VERSION ""

NS_ :

BS_ :

BU_ : mobileye vdcl_pc

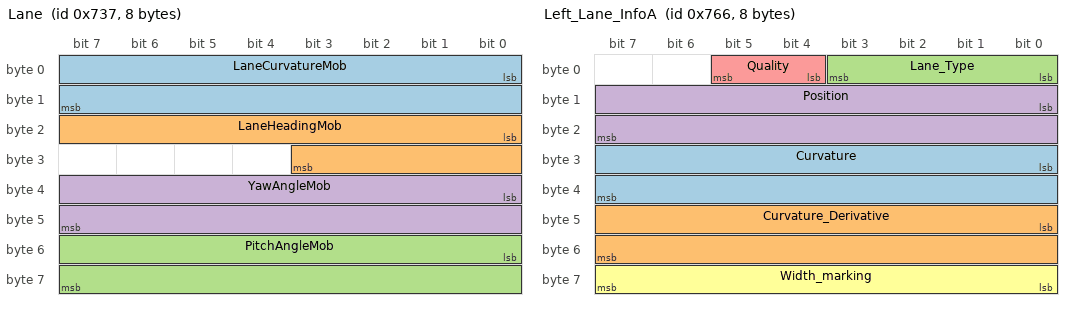
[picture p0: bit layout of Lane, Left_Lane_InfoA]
BO_ 1847 Lane: 8 mobileye
  SG_ LaneCurvatureMob : 0|16@1- (3.8099999999999991e-006,0) [-0.12|0.12] "1/m" vdcl_pc
  SG_ LaneHeadingMob : 16|12@1- (0.00050000000000000001,0) [-1|1] "rad" vdcl_pc
  SG_ PitchAngleMob : 48|16@1+ (1.9073486328125e-006,-0.062498092651367201) [-0.050000000000000003|0.050000000000000003] "rad" vdcl_pc
  SG_ YawAngleMob : 32|16@1+ (0.0009765625,-31.9990234375) [0|1000] "rad" vdcl_pc

BO_ 1894 Left_Lane_InfoA: 8 mobileye
  SG_ Curvature : 24|16@1+ (9.7655999999999963e-007,-0.03199894151999999) [-0.02|0.02] "" vdcl_pc
  SG_ Curvature_Derivative : 40|16@1+ (3.7252902984619149e-009,-0.0001220665899999999) [-0.00012|0.00012] "" vdcl_pc
  SG_ Lane_Type : 0|4@1+ (1,0) [0|1000] "" vdcl_pc
  SG_ Position : 8|16@1- (0.00390625,0) [-127|128] "m" vdcl_pc
  SG_ Quality : 4|2@1+ (1,0) [0|1000] "" vdcl_pc
  SG_ Width_marking : 56|8@1+ (0.01,0) [0|2.5] "" vdcl_pc

BO_ 1895 Left_Lane_InfoB: 8 mobileye
  SG_ Heading_Angle : 0|16@1+ (0.00097656000000000001,-31.9990234375) [-0.35699999999999987|0.35699999999999987] "radians" vdcl_pc
  SG_ Lane_View_Range : 16|15@1+ (0.00390625,0) [0|127.996] "meter" vdcl_pc

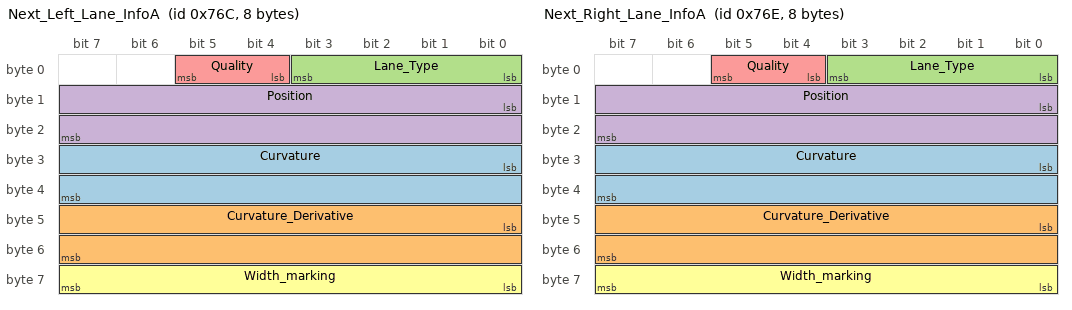
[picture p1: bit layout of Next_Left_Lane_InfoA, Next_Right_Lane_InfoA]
BO_ 1900 Next_Left_Lane_InfoA: 8 mobileye
  SG_ Curvature : 24|16@1+ (9.7655999999999963e-007,-0.031998941500000003) [-0.02|0.02] "" vdcl_pc
  SG_ Curvature_Derivative : 40|16@1+ (3.7252903000000002e-009,-0.0001220665899999999) [-0.00012|0.00012] "" vdcl_pc
  SG_ Lane_Type : 0|4@1+ (1,0) [0|1000] "" vdcl_pc
  SG_ Position : 8|16@1- (0.00390625,0) [-127|128] "" vdcl_pc
  SG_ Quality : 4|2@1+ (1,0) [0|1000] "" vdcl_pc
  SG_ Width_marking : 56|8@1+ (0.01,0) [0|2.5] "" vdcl_pc

BO_ 1901 Next_Left_Lane_InfoB: 8 mobileye
  SG_ Heading_Angle : 0|16@1+ (0.00097656000000000001,-31.999023399999999) [-0.35699999999999987|0.35699999999999987] "" vdcl_pc
  SG_ Lane_View_Range : 16|15@1+ (0.00390625,0) [0|127.996] "" vdcl_pc

BO_ 1902 Next_Right_Lane_InfoA: 8 mobileye
  SG_ Curvature : 24|16@1+ (9.7655999999999963e-007,-0.031998941500000003) [-0.02|0.02] "" vdcl_pc
  SG_ Curvature_Derivative : 40|16@1+ (3.7252903000000002e-009,-0.0001220665899999999) [-0.00012|0.00012] "" vdcl_pc
  SG_ Lane_Type : 0|4@1+ (1,0) [0|1000] "" vdcl_pc
  SG_ Position : 8|16@1- (0.00390625,0) [-127|128] "" vdcl_pc
  SG_ Quality : 4|2@1+ (1,0) [0|1000] "" vdcl_pc
  SG_ Width_marking : 56|8@1+ (0.01,0) [0|2.5] "" vdcl_pc

BO_ 1903 Next_Right_Lane_InfoB: 8 mobileye
  SG_ Heading_Angle : 0|16@1+ (0.00097656000000000001,-31.999023399999999) [-0.35699999999999987|0.35699999999999987] "" vdcl_pc
  SG_ Lane_View_Range : 16|15@1+ (0.00390625,0) [0|127.996] "" vdcl_pc

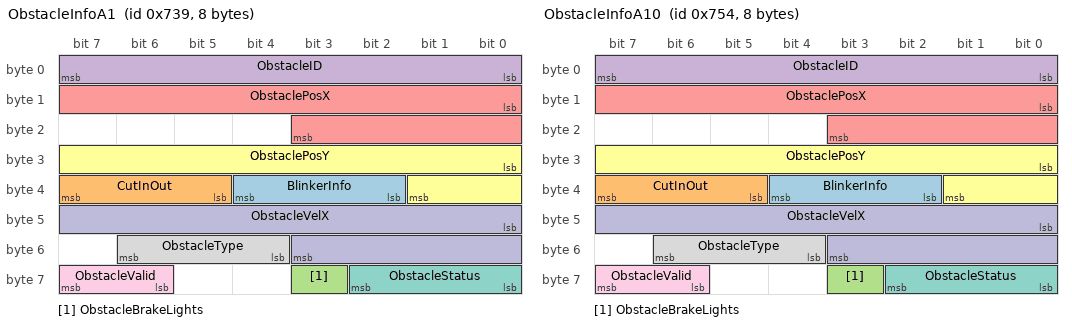
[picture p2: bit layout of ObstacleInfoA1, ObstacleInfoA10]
BO_ 1849 ObstacleInfoA1: 8 mobileye
  SG_ BlinkerInfo : 34|3@1+ (1,0) [0|1000] "" vdcl_pc
  SG_ CutInOut : 37|3@1+ (1,0) [0|1000] "" vdcl_pc
  SG_ ObstacleBrakeLights : 59|1@1+ (1,0) [0|1000] "" vdcl_pc
  SG_ ObstacleID : 0|8@1+ (1,0) [0|1000] "" vdcl_pc
  SG_ ObstaclePosX : 8|12@1+ (0.0625,0) [0|250] "m" vdcl_pc
  SG_ ObstaclePosY : 24|10@1- (0.0625,0) [-31.93|31.93] "m" vdcl_pc
  SG_ ObstacleStatus : 56|3@1+ (1,0) [0|1000] "" vdcl_pc
  SG_ ObstacleType : 52|3@1+ (1,0) [0|7] "" vdcl_pc
  SG_ ObstacleValid : 62|2@1+ (1,0) [0|1000] "" vdcl_pc
  SG_ ObstacleVelX : 40|12@1- (0.0625,0) [-127.93000000000001|127.93000000000001] "m/s" vdcl_pc

BO_ 1876 ObstacleInfoA10: 8 mobileye
  SG_ BlinkerInfo : 34|3@1+ (1,0) [0|1000] "" vdcl_pc
  SG_ CutInOut : 37|3@1+ (1,0) [0|1000] "" vdcl_pc
  SG_ ObstacleBrakeLights : 59|1@1+ (1,0) [0|1000] "" vdcl_pc
  SG_ ObstacleID : 0|8@1+ (1,0) [0|1000] "" vdcl_pc
  SG_ ObstaclePosX : 8|12@1+ (0.0625,0) [0|250] "m" vdcl_pc
  SG_ ObstaclePosY : 24|10@1- (0.0625,0) [-31.93|31.93] "m" vdcl_pc
  SG_ ObstacleStatus : 56|3@1+ (1,0) [0|1000] "" vdcl_pc
  SG_ ObstacleType : 52|3@1+ (1,0) [0|7] "" vdcl_pc
  SG_ ObstacleValid : 62|2@1+ (1,0) [0|1000] "" vdcl_pc
  SG_ ObstacleVelX : 40|12@1- (0.0625,0) [-127.93000000000001|127.93000000000001] "m/s" vdcl_pc

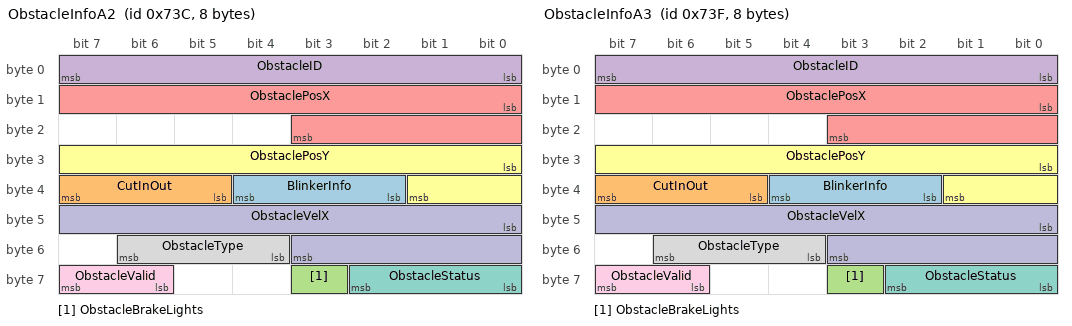
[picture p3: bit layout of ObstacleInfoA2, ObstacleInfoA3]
BO_ 1852 ObstacleInfoA2: 8 mobileye
  SG_ BlinkerInfo : 34|3@1+ (1,0) [0|1000] "" vdcl_pc
  SG_ CutInOut : 37|3@1+ (1,0) [0|1000] "" vdcl_pc
  SG_ ObstacleBrakeLights : 59|1@1+ (1,0) [0|1000] "" vdcl_pc
  SG_ ObstacleID : 0|8@1+ (1,0) [0|1000] "" vdcl_pc
  SG_ ObstaclePosX : 8|12@1+ (0.0625,0) [0|250] "m" vdcl_pc
  SG_ ObstaclePosY : 24|10@1- (0.0625,0) [-31.93|31.93] "m" vdcl_pc
  SG_ ObstacleStatus : 56|3@1+ (1,0) [0|1000] "" vdcl_pc
  SG_ ObstacleType : 52|3@1+ (1,0) [0|7] "" vdcl_pc
  SG_ ObstacleValid : 62|2@1+ (1,0) [0|1000] "" vdcl_pc
  SG_ ObstacleVelX : 40|12@1- (0.0625,0) [-127.93000000000001|127.93000000000001] "m/s" vdcl_pc

BO_ 1855 ObstacleInfoA3: 8 mobileye
  SG_ BlinkerInfo : 34|3@1+ (1,0) [0|1000] "" vdcl_pc
  SG_ CutInOut : 37|3@1+ (1,0) [0|1000] "" vdcl_pc
  SG_ ObstacleBrakeLights : 59|1@1+ (1,0) [0|1000] "" vdcl_pc
  SG_ ObstacleID : 0|8@1+ (1,0) [0|1000] "" vdcl_pc
  SG_ ObstaclePosX : 8|12@1+ (0.0625,0) [0|250] "m" vdcl_pc
  SG_ ObstaclePosY : 24|10@1- (0.0625,0) [-31.93|31.93] "m" vdcl_pc
  SG_ ObstacleStatus : 56|3@1+ (1,0) [0|1000] "" vdcl_pc
  SG_ ObstacleType : 52|3@1+ (1,0) [0|7] "" vdcl_pc
  SG_ ObstacleValid : 62|2@1+ (1,0) [0|1000] "" vdcl_pc
  SG_ ObstacleVelX : 40|12@1- (0.0625,0) [-127.93000000000001|127.93000000000001] "m/s" vdcl_pc

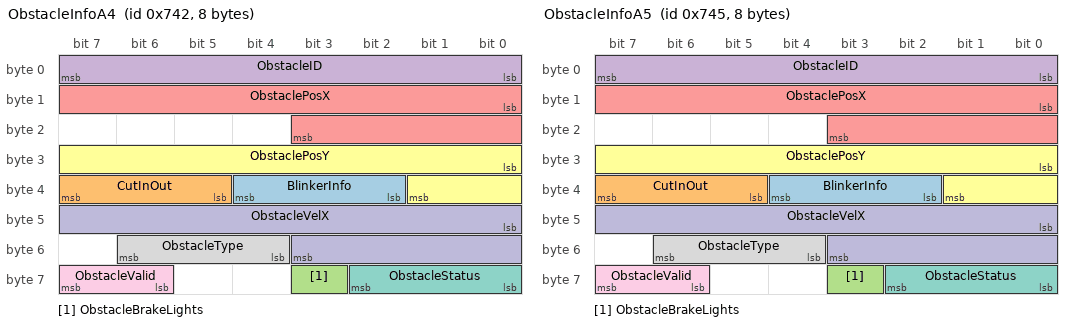
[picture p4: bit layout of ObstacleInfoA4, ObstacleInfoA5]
BO_ 1858 ObstacleInfoA4: 8 mobileye
  SG_ BlinkerInfo : 34|3@1+ (1,0) [0|1000] "" vdcl_pc
  SG_ CutInOut : 37|3@1+ (1,0) [0|1000] "" vdcl_pc
  SG_ ObstacleBrakeLights : 59|1@1+ (1,0) [0|1000] "" vdcl_pc
  SG_ ObstacleID : 0|8@1+ (1,0) [0|1000] "" vdcl_pc
  SG_ ObstaclePosX : 8|12@1+ (0.0625,0) [0|250] "m" vdcl_pc
  SG_ ObstaclePosY : 24|10@1- (0.0625,0) [-31.93|31.93] "m" vdcl_pc
  SG_ ObstacleStatus : 56|3@1+ (1,0) [0|1000] "" vdcl_pc
  SG_ ObstacleType : 52|3@1+ (1,0) [0|7] "" vdcl_pc
  SG_ ObstacleValid : 62|2@1+ (1,0) [0|1000] "" vdcl_pc
  SG_ ObstacleVelX : 40|12@1- (0.0625,0) [-127.93000000000001|127.93000000000001] "m/s" vdcl_pc

BO_ 1861 ObstacleInfoA5: 8 mobileye
  SG_ BlinkerInfo : 34|3@1+ (1,0) [0|1000] "" vdcl_pc
  SG_ CutInOut : 37|3@1+ (1,0) [0|1000] "" vdcl_pc
  SG_ ObstacleBrakeLights : 59|1@1+ (1,0) [0|1000] "" vdcl_pc
  SG_ ObstacleID : 0|8@1+ (1,0) [0|1000] "" vdcl_pc
  SG_ ObstaclePosX : 8|12@1+ (0.0625,0) [0|250] "m" vdcl_pc
  SG_ ObstaclePosY : 24|10@1- (0.0625,0) [-31.93|31.93] "m" vdcl_pc
  SG_ ObstacleStatus : 56|3@1+ (1,0) [0|1000] "" vdcl_pc
  SG_ ObstacleType : 52|3@1+ (1,0) [0|7] "" vdcl_pc
  SG_ ObstacleValid : 62|2@1+ (1,0) [0|1000] "" vdcl_pc
  SG_ ObstacleVelX : 40|12@1- (0.0625,0) [-127.93000000000001|127.93000000000001] "m/s" vdcl_pc

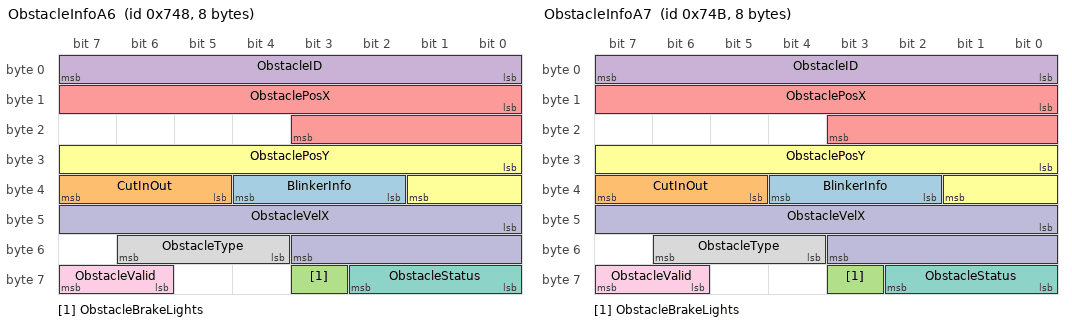
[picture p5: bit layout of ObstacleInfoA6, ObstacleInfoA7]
BO_ 1864 ObstacleInfoA6: 8 mobileye
  SG_ BlinkerInfo : 34|3@1+ (1,0) [0|1000] "" vdcl_pc
  SG_ CutInOut : 37|3@1+ (1,0) [0|1000] "" vdcl_pc
  SG_ ObstacleBrakeLights : 59|1@1+ (1,0) [0|1000] "" vdcl_pc
  SG_ ObstacleID : 0|8@1+ (1,0) [0|1000] "" vdcl_pc
  SG_ ObstaclePosX : 8|12@1+ (0.0625,0) [0|250] "m" vdcl_pc
  SG_ ObstaclePosY : 24|10@1- (0.0625,0) [-31.93|31.93] "m" vdcl_pc
  SG_ ObstacleStatus : 56|3@1+ (1,0) [0|1000] "" vdcl_pc
  SG_ ObstacleType : 52|3@1+ (1,0) [0|7] "" vdcl_pc
  SG_ ObstacleValid : 62|2@1+ (1,0) [0|1000] "" vdcl_pc
  SG_ ObstacleVelX : 40|12@1- (0.0625,0) [-127.93000000000001|127.93000000000001] "m/s" vdcl_pc

BO_ 1867 ObstacleInfoA7: 8 mobileye
  SG_ BlinkerInfo : 34|3@1+ (1,0) [0|1000] "" vdcl_pc
  SG_ CutInOut : 37|3@1+ (1,0) [0|1000] "" vdcl_pc
  SG_ ObstacleBrakeLights : 59|1@1+ (1,0) [0|1000] "" vdcl_pc
  SG_ ObstacleID : 0|8@1+ (1,0) [0|1000] "" vdcl_pc
  SG_ ObstaclePosX : 8|12@1+ (0.0625,0) [0|250] "m" vdcl_pc
  SG_ ObstaclePosY : 24|10@1- (0.0625,0) [-31.93|31.93] "m" vdcl_pc
  SG_ ObstacleStatus : 56|3@1+ (1,0) [0|1000] "" vdcl_pc
  SG_ ObstacleType : 52|3@1+ (1,0) [0|7] "" vdcl_pc
  SG_ ObstacleValid : 62|2@1+ (1,0) [0|1000] "" vdcl_pc
  SG_ ObstacleVelX : 40|12@1- (0.0625,0) [-127.93000000000001|127.93000000000001] "m/s" vdcl_pc

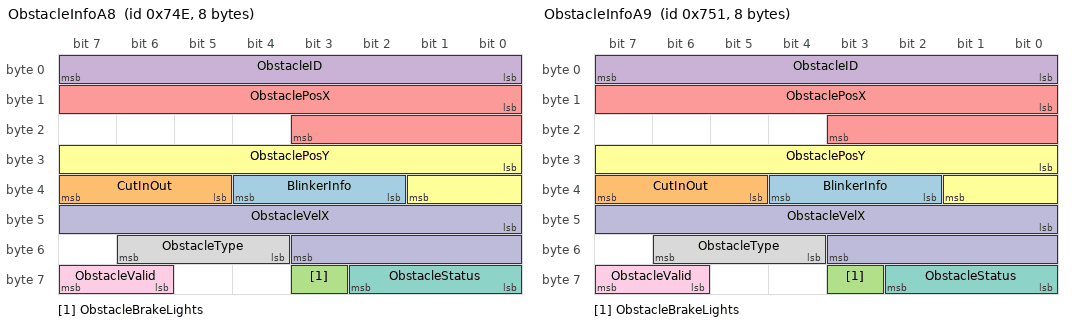
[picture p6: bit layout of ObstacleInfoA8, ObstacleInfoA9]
BO_ 1870 ObstacleInfoA8: 8 mobileye
  SG_ BlinkerInfo : 34|3@1+ (1,0) [0|1000] "" vdcl_pc
  SG_ CutInOut : 37|3@1+ (1,0) [0|1000] "" vdcl_pc
  SG_ ObstacleBrakeLights : 59|1@1+ (1,0) [0|1000] "" vdcl_pc
  SG_ ObstacleID : 0|8@1+ (1,0) [0|1000] "" vdcl_pc
  SG_ ObstaclePosX : 8|12@1+ (0.0625,0) [0|250] "m" vdcl_pc
  SG_ ObstaclePosY : 24|10@1- (0.0625,0) [-31.93|31.93] "m" vdcl_pc
  SG_ ObstacleStatus : 56|3@1+ (1,0) [0|1000] "" vdcl_pc
  SG_ ObstacleType : 52|3@1+ (1,0) [0|7] "" vdcl_pc
  SG_ ObstacleValid : 62|2@1+ (1,0) [0|1000] "" vdcl_pc
  SG_ ObstacleVelX : 40|12@1- (0.0625,0) [-127.93000000000001|127.93000000000001] "m/s" vdcl_pc

BO_ 1873 ObstacleInfoA9: 8 mobileye
  SG_ BlinkerInfo : 34|3@1+ (1,0) [0|1000] "" vdcl_pc
  SG_ CutInOut : 37|3@1+ (1,0) [0|1000] "" vdcl_pc
  SG_ ObstacleBrakeLights : 59|1@1+ (1,0) [0|1000] "" vdcl_pc
  SG_ ObstacleID : 0|8@1+ (1,0) [0|1000] "" vdcl_pc
  SG_ ObstaclePosX : 8|12@1+ (0.0625,0) [0|250] "m" vdcl_pc
  SG_ ObstaclePosY : 24|10@1- (0.0625,0) [-31.93|31.93] "m" vdcl_pc
  SG_ ObstacleStatus : 56|3@1+ (1,0) [0|1000] "" vdcl_pc
  SG_ ObstacleType : 52|3@1+ (1,0) [0|7] "" vdcl_pc
  SG_ ObstacleValid : 62|2@1+ (1,0) [0|1000] "" vdcl_pc
  SG_ ObstacleVelX : 40|12@1- (0.0625,0) [-127.93000000000001|127.93000000000001] "m/s" vdcl_pc

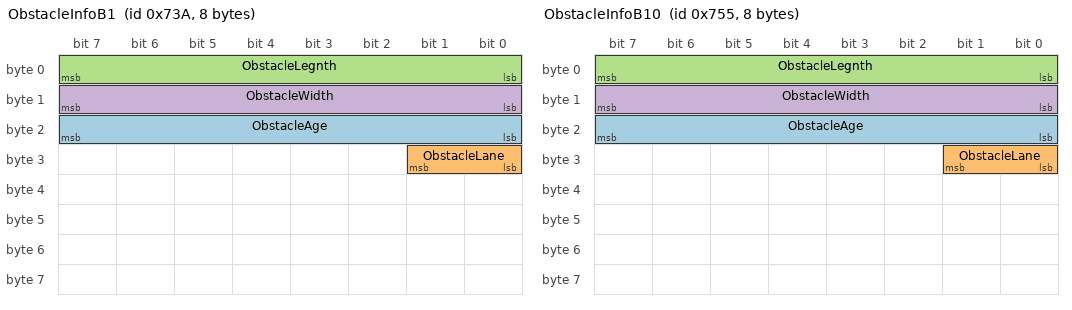
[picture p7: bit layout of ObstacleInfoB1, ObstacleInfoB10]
BO_ 1850 ObstacleInfoB1: 8 mobileye
  SG_ ObstacleAge : 16|8@1+ (1,0) [0|1000] "" vdcl_pc
  SG_ ObstacleLane : 24|2@1+ (1,0) [0|1000] "" vdcl_pc
  SG_ ObstacleLegnth : 0|8@1+ (0.5,0) [0|31] "m" vdcl_pc
  SG_ ObstacleWidth : 8|8@1+ (0.050000000000000003,0) [0|12.5] "" vdcl_pc

BO_ 1877 ObstacleInfoB10: 8 mobileye
  SG_ ObstacleAge : 16|8@1+ (1,0) [0|1000] "" vdcl_pc
  SG_ ObstacleLane : 24|2@1+ (1,0) [0|1000] "" vdcl_pc
  SG_ ObstacleLegnth : 0|8@1+ (0.5,0) [0|31] "m" vdcl_pc
  SG_ ObstacleWidth : 8|8@1+ (0.050000000000000003,0) [0|12.5] "" vdcl_pc

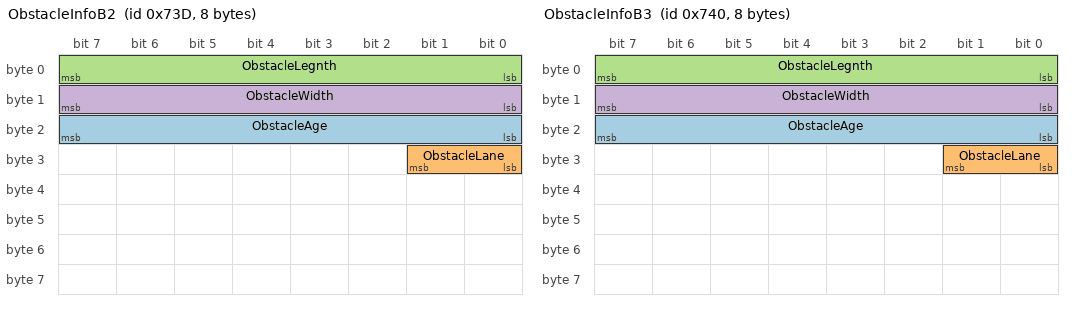
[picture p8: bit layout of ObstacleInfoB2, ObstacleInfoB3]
BO_ 1853 ObstacleInfoB2: 8 mobileye
  SG_ ObstacleAge : 16|8@1+ (1,0) [0|1000] "" vdcl_pc
  SG_ ObstacleLane : 24|2@1+ (1,0) [0|1000] "" vdcl_pc
  SG_ ObstacleLegnth : 0|8@1+ (0.5,0) [0|31] "m" vdcl_pc
  SG_ ObstacleWidth : 8|8@1+ (0.050000000000000003,0) [0|12.5] "" vdcl_pc

BO_ 1856 ObstacleInfoB3: 8 mobileye
  SG_ ObstacleAge : 16|8@1+ (1,0) [0|1000] "" vdcl_pc
  SG_ ObstacleLane : 24|2@1+ (1,0) [0|1000] "" vdcl_pc
  SG_ ObstacleLegnth : 0|8@1+ (0.5,0) [0|31] "m" vdcl_pc
  SG_ ObstacleWidth : 8|8@1+ (0.050000000000000003,0) [0|12.5] "" vdcl_pc

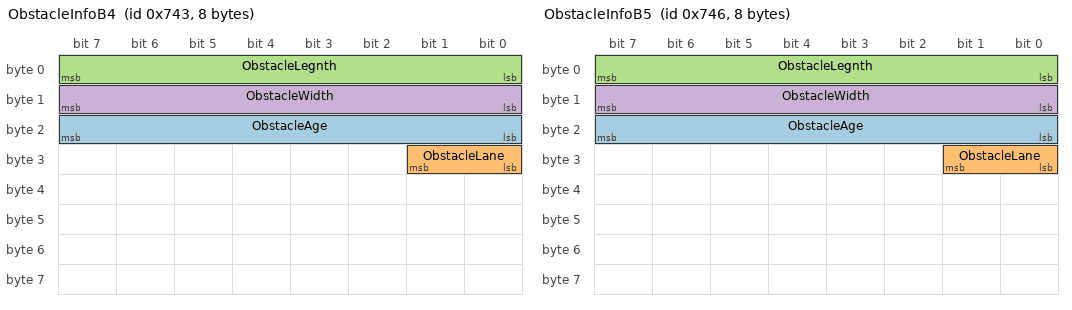
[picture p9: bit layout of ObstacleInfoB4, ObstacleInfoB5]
BO_ 1859 ObstacleInfoB4: 8 mobileye
  SG_ ObstacleAge : 16|8@1+ (1,0) [0|1000] "" vdcl_pc
  SG_ ObstacleLane : 24|2@1+ (1,0) [0|1000] "" vdcl_pc
  SG_ ObstacleLegnth : 0|8@1+ (0.5,0) [0|31] "m" vdcl_pc
  SG_ ObstacleWidth : 8|8@1+ (0.050000000000000003,0) [0|12.5] "" vdcl_pc

BO_ 1862 ObstacleInfoB5: 8 mobileye
  SG_ ObstacleAge : 16|8@1+ (1,0) [0|1000] "" vdcl_pc
  SG_ ObstacleLane : 24|2@1+ (1,0) [0|1000] "" vdcl_pc
  SG_ ObstacleLegnth : 0|8@1+ (0.5,0) [0|31] "m" vdcl_pc
  SG_ ObstacleWidth : 8|8@1+ (0.050000000000000003,0) [0|12.5] "" vdcl_pc

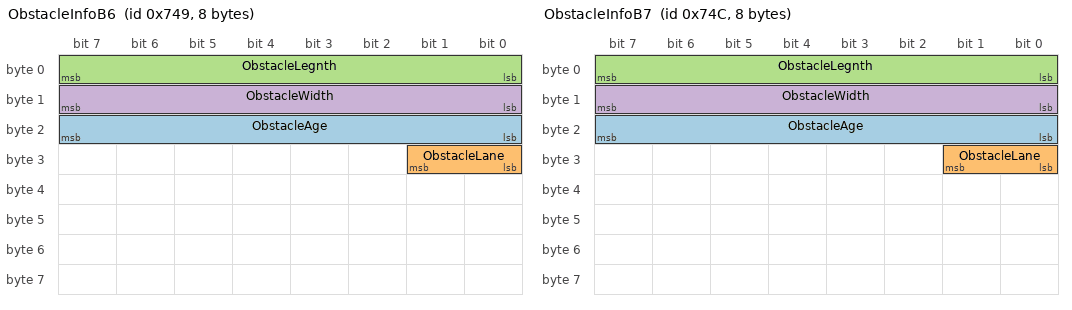
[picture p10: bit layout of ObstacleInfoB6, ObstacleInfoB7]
BO_ 1865 ObstacleInfoB6: 8 mobileye
  SG_ ObstacleAge : 16|8@1+ (1,0) [0|1000] "" vdcl_pc
  SG_ ObstacleLane : 24|2@1+ (1,0) [0|1000] "" vdcl_pc
  SG_ ObstacleLegnth : 0|8@1+ (0.5,0) [0|31] "m" vdcl_pc
  SG_ ObstacleWidth : 8|8@1+ (0.050000000000000003,0) [0|12.5] "" vdcl_pc

BO_ 1868 ObstacleInfoB7: 8 mobileye
  SG_ ObstacleAge : 16|8@1+ (1,0) [0|1000] "" vdcl_pc
  SG_ ObstacleLane : 24|2@1+ (1,0) [0|1000] "" vdcl_pc
  SG_ ObstacleLegnth : 0|8@1+ (0.5,0) [0|31] "m" vdcl_pc
  SG_ ObstacleWidth : 8|8@1+ (0.050000000000000003,0) [0|12.5] "" vdcl_pc

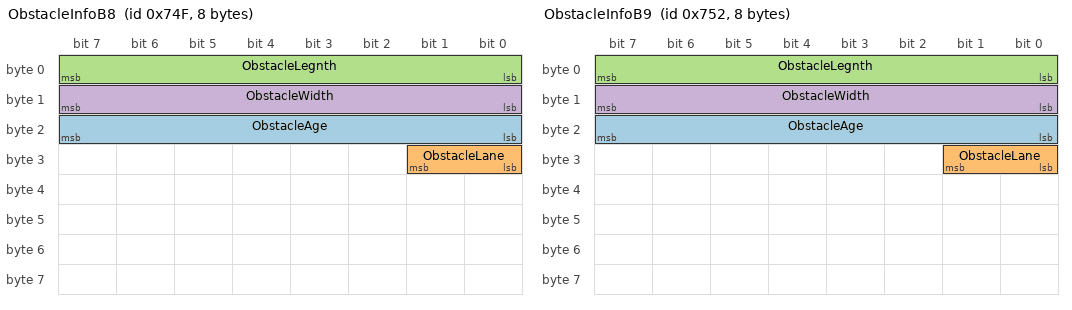
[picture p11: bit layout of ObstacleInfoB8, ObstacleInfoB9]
BO_ 1871 ObstacleInfoB8: 8 mobileye
  SG_ ObstacleAge : 16|8@1+ (1,0) [0|1000] "" vdcl_pc
  SG_ ObstacleLane : 24|2@1+ (1,0) [0|1000] "" vdcl_pc
  SG_ ObstacleLegnth : 0|8@1+ (0.050000000000000003,0) [0|31] "m" vdcl_pc
  SG_ ObstacleWidth : 8|8@1+ (0.050000000000000003,0) [0|12.5] "" vdcl_pc

BO_ 1874 ObstacleInfoB9: 8 mobileye
  SG_ ObstacleAge : 16|8@1+ (1,0) [0|1000] "" vdcl_pc
  SG_ ObstacleLane : 24|2@1+ (1,0) [0|1000] "" vdcl_pc
  SG_ ObstacleLegnth : 0|8@1+ (0.5,0) [0|31] "m" vdcl_pc
  SG_ ObstacleWidth : 8|8@1+ (0.050000000000000003,0) [0|12.5] "" vdcl_pc

BO_ 1851 ObstacleInfoC1: 8 mobileye
  SG_ ObstacleAngle : 48|16@1- (0.01,0) [-327.68000000000001|327.68000000000001] "degree" vdcl_pc
  SG_ ObstacleAngleRate : 0|16@1- (0.01,0) [-327.68000000000001|327.68000000000001] "deg/s" vdcl_pc

BO_ 1878 ObstacleInfoC110: 8 mobileye
  SG_ ObstacleAngle : 48|16@1- (0.01,0) [-327.68000000000001|327.68000000000001] "degree" vdcl_pc
  SG_ ObstacleAngleRate : 0|16@1- (0.01,0) [-327.68000000000001|327.68000000000001] "deg/s" vdcl_pc

BO_ 1854 ObstacleInfoC2: 8 mobileye
  SG_ ObstacleAngle : 48|16@1- (0.01,0) [-327.68000000000001|327.68000000000001] "degree" vdcl_pc
  SG_ ObstacleAngleRate : 0|16@1- (0.01,0) [-327.68000000000001|327.68000000000001] "deg/s" vdcl_pc

BO_ 1857 ObstacleInfoC3: 8 mobileye
  SG_ ObstacleAngle : 48|16@1- (0.01,0) [-327.68000000000001|327.68000000000001] "degree" vdcl_pc
  SG_ ObstacleAngleRate : 0|16@1- (0.01,0) [-327.68000000000001|327.68000000000001] "deg/s" vdcl_pc

BO_ 1860 ObstacleInfoC4: 8 mobileye
  SG_ ObstacleAngle : 48|16@1- (0.01,0) [-327.68000000000001|327.68000000000001] "degree" vdcl_pc
  SG_ ObstacleAngleRate : 0|16@1- (0.01,0) [-327.68000000000001|327.68000000000001] "deg/s" vdcl_pc

BO_ 1863 ObstacleInfoC5: 8 mobileye
  SG_ ObstacleAngle : 48|16@1- (0.01,0) [-327.68000000000001|327.68000000000001] "degree" vdcl_pc
  SG_ ObstacleAngleRate : 0|16@1- (0.01,0) [-327.68000000000001|327.68000000000001] "deg/s" vdcl_pc

BO_ 1866 ObstacleInfoC6: 8 mobileye
  SG_ ObstacleAngle : 48|16@1- (0.01,0) [-327.68000000000001|327.68000000000001] "degree" vdcl_pc
  SG_ ObstacleAngleRate : 0|16@1- (0.01,0) [-327.68000000000001|327.68000000000001] "deg/s" vdcl_pc

BO_ 1869 ObstacleInfoC7: 8 mobileye
  SG_ ObstacleAngle : 48|16@1- (0.01,0) [-327.68000000000001|327.68000000000001] "degree" vdcl_pc
  SG_ ObstacleAngleRate : 0|16@1- (0.01,0) [-327.68000000000001|327.68000000000001] "deg/s" vdcl_pc

BO_ 1872 ObstacleInfoC8: 8 mobileye
  SG_ ObstacleAngle : 48|16@1- (0.01,0) [-327.68000000000001|327.68000000000001] "degree" vdcl_pc
  SG_ ObstacleAngleRate : 0|16@1- (0.01,0) [-327.68000000000001|327.68000000000001] "deg/s" vdcl_pc

BO_ 1875 ObstacleInfoC9: 8 mobileye
  SG_ ObstacleAngle : 48|16@1- (0.01,0) [-327.68000000000001|327.68000000000001] "degree" vdcl_pc
  SG_ ObstacleAngleRate : 0|16@1- (0.01,0) [-327.68000000000001|327.68000000000001] "deg/s" vdcl_pc

BO_ 1848 ObstacleStatus: 8 mobileye
  SG_ NumOfObsMob : 0|8@1+ (1,0) [0|255] "" vdcl_pc
  SG_ TimestampMob : 8|8@1+ (1,0) [0|255] "ms" vdcl_pc

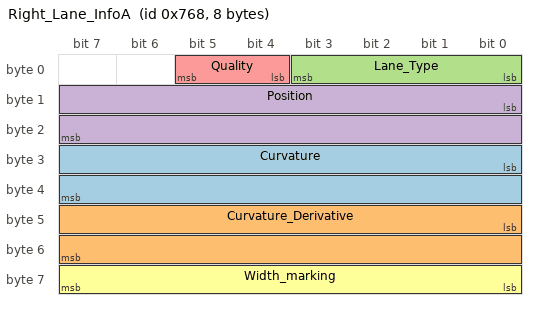
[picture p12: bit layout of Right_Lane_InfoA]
BO_ 1896 Right_Lane_InfoA: 8 mobileye
  SG_ Curvature : 24|16@1+ (9.7655999999999963e-007,-0.031998941500000003) [-0.02|0.02] "" vdcl_pc
  SG_ Curvature_Derivative : 40|16@1+ (3.7252903000000002e-009,-0.0001220665899999999) [-0.00012|0.00012] "" vdcl_pc
  SG_ Lane_Type : 0|4@1+ (1,0) [0|1000] "" vdcl_pc
  SG_ Position : 8|16@1- (0.00390625,128) [0|-127] "" vdcl_pc
  SG_ Quality : 4|2@1+ (1,0) [0|1000] "" vdcl_pc
  SG_ Width_marking : 56|8@1+ (0.01,0) [0|2.5] "" vdcl_pc

BO_ 1897 Right_Lane_InfoB: 8 mobileye
  SG_ Heading_Angle : 0|16@1+ (0.00097656000000000001,-31.999023399999999) [-0.35699999999999987|0.35699999999999987] "" vdcl_pc
  SG_ Lane_View_Range : 16|15@1+ (0.00390625,0) [0|127.996] "" vdcl_pc

CM_ SG_ 1849 BlinkerInfo "\84h 0=unavailable
\84h 1= off
\84h 2= left
\84h 3= right
\84h 4=both";
CM_ SG_ 1849 CutInOut "0= undefined
\84h 1= in host lane
\84h 2= out host lane
\84h 3=Cut in
\84h 4=Cut out";
CM_ SG_ 1847 LaneCurvatureMob "The Curvature (a) parameter in the equation: y= ax^2 + bx+ c
To extract the road radius (r) from curvature (a): r = 1/(2*a).";
CM_ SG_ 1847 LaneHeadingMob "The Heading (b) parameter in the equation: y= ax^2 + bx+ c";
CM_ SG_ 1851 ObstacleAngle "Angle to Center of Obstacle in degrees. 0 indicates that the obstacle is in exactly in front of us (along the longitudinal axis); a positive angle indicates that the obstacle is to the right (clockwise axis system). This value is calculated from the reference point, and is based on the obstacle\A1\AFs location in the image and the distance estimation in order to provide measurements in the real world. The angle error can have errors with correlation to the distance measurements error.";
CM_ SG_ 1851 ObstacleAngleRate "Angle rate of Center of Obstacle in degrees/sec. A negative angle rate indicates that the obstacle has moved to the left (clockwise axis system). This value is calculated based on delta angles reported from the reference point in two consecutive frames.";
CM_ SG_ 1849 ObstacleBrakeLights "object\A1\AFs brake lights are on";
CM_ SG_ 1849 ObstacleID "Note: New obstacles are given the last used free ID.";
CM_ SG_ 1850 ObstacleLane "0
Not assigned
1
Ego lane
2
Next lane (left or right), or next next lane
3
Invalid signal";
CM_ SG_ 1849 ObstacleStatus "0
Undefined
1
Standing (never moved, back lights are on)
2
Stopped (movable)
3
Moving
4
Oncoming
5
Parked (never moved, back lights are off)
6
Unused";
CM_ SG_ 1849 ObstacleType "000 . Vehicle
001 . Truck
010 . Bike
011 . Ped
100 . Bicycle
101 . Unused
110 . Unused
111 . Unused";
CM_ SG_ 1847 PitchAngleMob "The pitch angle information of the host vehicle";
CM_ SG_ 1848 TimestampMob "Only the lowest 8 bits of the timestamp is given. The timestamp source is from the EyeQ image grabbing.";
CM_ SG_ 1847 YawAngleMob "The yaw angle information of the host vehicle";
BA_DEF_ "DBName" STRING;
BA_DEF_ "BusType" STRING;
BA_DEF_ BO_ "VFrameFormat" ENUM "StandardCAN","ExtendedCAN","reserved","J1939PG","reserved","reserved","reserved","reserved","reserved","reserved","reserved","reserved","reserved","reserved","StandardCAN_FD","ExtendedCAN_FD";
BA_DEF_ BO_ "GenMsgSendType" ENUM "Cyclic","Event","CyclicIfActive","SpontanWithDelay","CyclicAndSpontan","CyclicAndSpontanWithDelay";
BA_DEF_ BO_ "GenMsgCycleTime" INT 0 0;
BA_DEF_ SG_ "GenSigStartValue" FLOAT 0 0;
BA_DEF_DEF_ "DBName" "Mobileye_Protocol";
BA_DEF_DEF_ "BusType" "CAN";
BA_DEF_DEF_ "VFrameFormat" "StandardCAN";
BA_DEF_DEF_ "GenMsgSendType" "Cyclic";
BA_DEF_DEF_ "GenMsgCycleTime" 0;
BA_DEF_DEF_ "GenSigStartValue" 0;
BA_ "GenMsgCycleTime" BO_ 1847 100;
BA_ "GenMsgCycleTime" BO_ 1894 100;
BA_ "GenMsgCycleTime" BO_ 1895 100;
BA_ "GenMsgCycleTime" BO_ 1900 100;
BA_ "GenMsgCycleTime" BO_ 1901 100;
BA_ "GenMsgCycleTime" BO_ 1902 100;
BA_ "GenMsgCycleTime" BO_ 1903 100;
BA_ "GenMsgCycleTime" BO_ 1849 100;
BA_ "GenMsgCycleTime" BO_ 1876 100;
BA_ "GenMsgCycleTime" BO_ 1852 100;
BA_ "GenMsgCycleTime" BO_ 1855 100;
BA_ "GenMsgCycleTime" BO_ 1858 100;
BA_ "GenMsgCycleTime" BO_ 1861 100;
BA_ "GenMsgCycleTime" BO_ 1864 100;
BA_ "GenMsgCycleTime" BO_ 1867 100;
BA_ "GenMsgCycleTime" BO_ 1870 100;
BA_ "GenMsgCycleTime" BO_ 1873 100;
BA_ "GenMsgCycleTime" BO_ 1850 100;
BA_ "GenMsgCycleTime" BO_ 1877 100;
BA_ "GenMsgCycleTime" BO_ 1853 100;
BA_ "GenMsgCycleTime" BO_ 1856 100;
BA_ "GenMsgCycleTime" BO_ 1859 100;
BA_ "GenMsgCycleTime" BO_ 1862 100;
BA_ "GenMsgCycleTime" BO_ 1865 100;
BA_ "GenMsgCycleTime" BO_ 1868 100;
BA_ "GenMsgCycleTime" BO_ 1871 100;
BA_ "GenMsgCycleTime" BO_ 1874 100;
BA_ "GenMsgCycleTime" BO_ 1851 100;
BA_ "GenMsgCycleTime" BO_ 1878 100;
BA_ "GenMsgCycleTime" BO_ 1854 100;
BA_ "GenMsgCycleTime" BO_ 1857 100;
BA_ "GenMsgCycleTime" BO_ 1860 100;
BA_ "GenMsgCycleTime" BO_ 1863 100;
BA_ "GenMsgCycleTime" BO_ 1866 100;
BA_ "GenMsgCycleTime" BO_ 1869 100;
BA_ "GenMsgCycleTime" BO_ 1872 100;
BA_ "GenMsgCycleTime" BO_ 1875 100;
BA_ "GenMsgCycleTime" BO_ 1848 100;
BA_ "GenMsgCycleTime" BO_ 1896 100;
BA_ "GenMsgCycleTime" BO_ 1897 100;
BA_ "GenSigStartValue" SG_ 1847 PitchAngleMob 32767.000000000007;
BA_ "GenSigStartValue" SG_ 1847 YawAngleMob 32767;
BA_ "GenSigStartValue" SG_ 1894 Curvature 32767.000000000004;
BA_ "GenSigStartValue" SG_ 1894 Curvature_Derivative 32767.000749015006;
BA_ "GenSigStartValue" SG_ 1895 Heading_Angle 32767.08388373474;
BA_ "GenSigStartValue" SG_ 1900 Curvature 32766.999979519962;
BA_ "GenSigStartValue" SG_ 1900 Curvature_Derivative 32767.000735486276;
BA_ "GenSigStartValue" SG_ 1901 Heading_Angle 32767.083845334641;
BA_ "GenSigStartValue" SG_ 1902 Curvature 32766.999979519962;
BA_ "GenSigStartValue" SG_ 1902 Curvature_Derivative 32767.000735486276;
BA_ "GenSigStartValue" SG_ 1903 Heading_Angle 32767.083845334641;
BA_ "GenSigStartValue" SG_ 1896 Curvature 32766.999979519962;
BA_ "GenSigStartValue" SG_ 1896 Curvature_Derivative 32767.000735486276;
BA_ "GenSigStartValue" SG_ 1896 Position -32768;
BA_ "GenSigStartValue" SG_ 1897 Heading_Angle 32767.083845334641;
